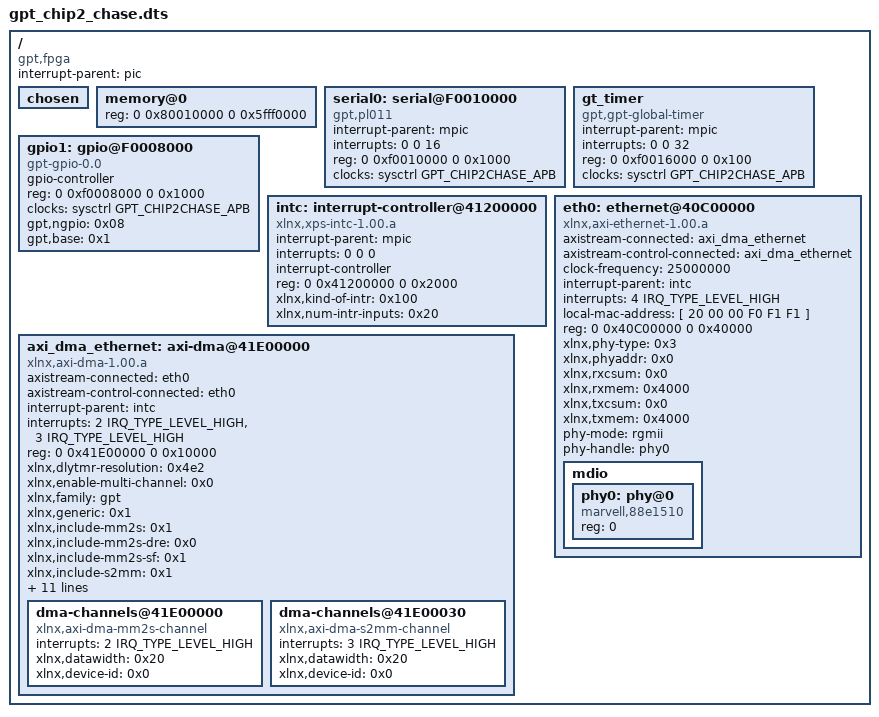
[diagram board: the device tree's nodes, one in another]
/*
 * dts file for GPT Chip2 FPGA
 *
 * Copyright (C) 2018, General Processor Techologies Inc.
 *
 * This program is free software; you can redistribute it and/or
 * modify it under the terms of the GNU General Public License as
 * published by the Free Software Foundation; either version 2 of
 * the License, or (at your option) any later version.
 */
 
/dts-v1/;
#include <dt-bindings/interrupt-controller/irq.h>
/include/ "gpt_chip2.dtsi"
#include <dt-bindings/clock/gpt,chip2chase-clock.h>

/ {
	compatible = "gpt,fpga", "gpt,chase";
	#address-cells = <2>;
	#size-cells = <2>;
	interrupt-parent = <&pic>;

        chosen {
	
    //bootargs = "root=/dev/nfs nolock nfsvers=4 rw nfsroot=192.168.1.22:/test ip=192.168.1.178:192.168.1.22:192.168.1.4:255.255.255.0:chip2fpga:eth0:off init=/linuxrc console=ttyAMA0,230400n8 nfsrootdebug rootwait ";
        };



	memory@0 {
		device_type = "memory";
	    	reg = <0 0x80010000 0 0x5fff0000>;
	};

	serial0: serial@F0010000 {
		compatible = "gpt,pl011";
		interrupt-parent = <&mpic>;
		interrupts = <0 0 16>;
		reg = <0 0xf0010000 0 0x1000>;
		clocks = <&sysctrl GPT_CHIP2CHASE_APB>;
		status = "ok";
	};
	
	gt_timer {
		compatible = "gpt,gpt-global-timer";
		interrupt-parent = <&mpic>;
		interrupts = <0 0 32>;
		reg = <0 0xf0016000 0 0x100>;
		clocks = <&sysctrl GPT_CHIP2CHASE_APB>;
		status = "ok";
	};

	gpio1: gpio@F0008000 {
		compatible = "gpt-gpio-0.0";
		//interrupt-parent = <&mpic>;
		//interrupts = <0 0 0>;
		//#interrupt-cells = <2>;
		//interrupt-controller ;
		#gpio-cells = <2>;		
		gpio-controller;
		reg = <0 0xf0008000 0 0x1000>;
		//clocks = <&refclk25mhz>;
		clocks = <&sysctrl GPT_CHIP2CHASE_APB>;
		gpt,ngpio = <0x08>;
		gpt,base = <0x1>;
		//intc-gpios = <&gpio1 0 GPIO_ACTIVE_HIGH>;
		status ="ok";
	};

	intc: interrupt-controller@41200000 {
		compatible = "xlnx,xps-intc-1.00.a";
		interrupt-parent = <&mpic>;
		interrupts = <0 0 0>;
		#interrupt-cells = <2>;
		interrupt-controller ;
		reg = <0 0x41200000 0 0x2000>;
		xlnx,kind-of-intr = <0x100>;
		xlnx,num-intr-inputs = <0x20>;
	};

 axi_dma_ethernet: axi-dma@41E00000 {
		axistream-connected = <&eth0>;
		axistream-control-connected = <&eth0>;
		compatible = "xlnx,axi-dma-1.00.a";
		interrupt-parent = <&intc>;
		interrupts = < 2 IRQ_TYPE_LEVEL_HIGH >,< 3 IRQ_TYPE_LEVEL_HIGH >;
		reg = <0 0x41E00000 0 0x10000 >;
	  	xlnx,dlytmr-resolution = <0x4e2>;
		xlnx,enable-multi-channel = <0x0>;
		xlnx,family = "gpt";
		xlnx,generic = <0x1>;
		xlnx,include-mm2s = <0x1>;
		xlnx,include-mm2s-dre = <0x0>;
		xlnx,include-mm2s-sf = <0x1>;
		xlnx,include-s2mm = <0x1>;
		xlnx,include-s2mm-dre = <0x0>;
		xlnx,include-s2mm-sf = <0x1>;
   	 	xlnx,instance = "AXI_DMA_Ethernet";
		xlnx,mm2s-burst-size = <0x10>;
		xlnx,num-mm2s-channels = <0x1>;
		xlnx,num-s2mm-channels = <0x1>;
		xlnx,prmry-is-aclk-async = <0x0>;
		xlnx,s2mm-burst-size = <0x10>;
		xlnx,sg-include-desc-queue = <0x0>;
		xlnx,sg-length-width = <0x0>;
		xlnx,sg-use-stsapp-length = <0x0>;
		status = "ok";
		dma-channels@41E00000 {
			compatible = "xlnx,axi-dma-mm2s-channel";
			interrupts = <2 IRQ_TYPE_LEVEL_HIGH >;
			xlnx,datawidth = <0x20>;
			xlnx,device-id = <0x0>;
		};

		dma-channels@41E00030 {
			compatible = "xlnx,axi-dma-s2mm-channel";
			interrupts = <3 IRQ_TYPE_LEVEL_HIGH >;
			xlnx,datawidth = <0x20>;
			xlnx,device-id = <0x0>;
		};
	};

	eth0:ethernet@40C00000 {
		axistream-connected = <&axi_dma_ethernet>;
		axistream-control-connected = <&axi_dma_ethernet>;
/*		clocks = <&refclk25mhz>;*/
		clock-names = "apb_pclk";
		clock-frequency = <25000000>;
		compatible = "xlnx,axi-ethernet-1.00.a";
		device_type = "network";
		interrupt-parent = <&intc>;
		interrupts = <4 IRQ_TYPE_LEVEL_HIGH >;
   		local-mac-address = [ 20 00 00 F0 F1 F1 ];        /****178***/
    		//local-mac-address = [ 20 00 00 F0 F1 F2 ];      /****179***/
    		//local-mac-address = [ 20 00 00 FF FF FF ];      /****180***/
		reg = < 0 0x40C00000 0 0x40000>;
		xlnx,phy-type = <0x3>;
	  	xlnx,phyaddr = <0x0>;
		xlnx,rxcsum = <0x0>;
		xlnx,rxmem = <0x4000>;
		xlnx,txcsum = <0x0>;
		xlnx,txmem = <0x4000>;
		phy-mode = "rgmii";
		phy-handle = <&phy0>;
		mdio {
			#address-cells = <1>;
			#size-cells = <0>;
			phy0: phy@0 {
				compatible = "marvell,88e1510";
				device_type = "ethernet-phy";
				reg = <0>;
			};
		};
	};
};
